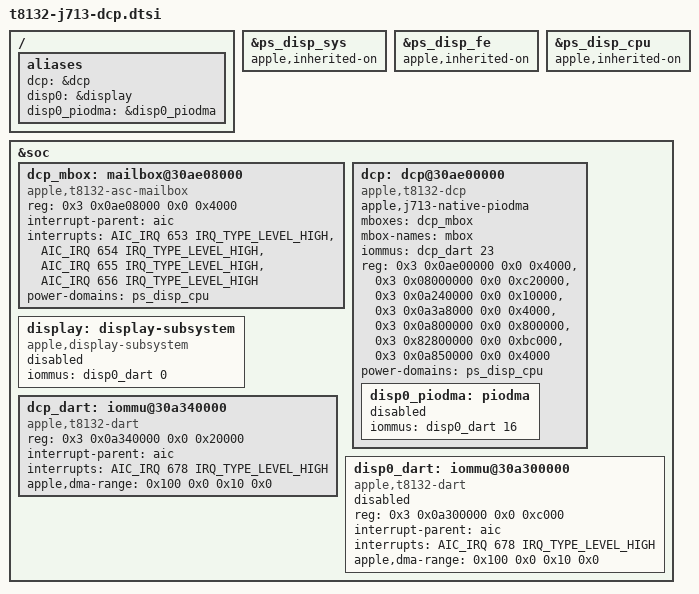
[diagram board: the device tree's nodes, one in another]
// SPDX-License-Identifier: GPL-2.0+ OR MIT
/*
 * J713 internal display resources from its live T8132 ADT.
 * Enable the DCP transport for explicit RTKit bring-up. Scanout and its DART
 * remain disabled. T8132 does not match the imported H17P display driver.
 */

/ {
	aliases {
		dcp = &dcp;
		disp0 = &display;
		disp0_piodma = &disp0_piodma;
	};
};

/* J713 capture: DISP_SYS=0xff, DISP_FE=0x20ff, DISP_CPU=0x1000030f.
 * Keep the inherited power/automatic-gating policy throughout bring-up.
 */
&ps_disp_sys {
	apple,inherited-on;
};

&ps_disp_fe {
	apple,inherited-on;
};

&ps_disp_cpu {
	apple,inherited-on;
};

&soc {
	dcp_mbox: mailbox@30ae08000 {
		compatible = "apple,t8132-asc-mailbox", "apple,asc-mailbox-v4";
		reg = <0x3 0x0ae08000 0x0 0x4000>;
		interrupt-parent = <&aic>;
		/* ADT pairs are not-empty/empty, as on the J713 MTP ASC. */
		interrupts = <AIC_IRQ 653 IRQ_TYPE_LEVEL_HIGH>,
			     <AIC_IRQ 654 IRQ_TYPE_LEVEL_HIGH>,
			     <AIC_IRQ 655 IRQ_TYPE_LEVEL_HIGH>,
			     <AIC_IRQ 656 IRQ_TYPE_LEVEL_HIGH>;
		interrupt-names = "send-empty", "send-not-empty",
				  "recv-empty", "recv-not-empty";
		power-domains = <&ps_disp_cpu>;
		#mbox-cells = <0>;
		status = "okay";
	};

	dcp: dcp@30ae00000 {
		compatible = "apple,t8132-dcp";
		/* m1n1 enables PIODMA only after validating every inherited mapping. */
		apple,j713-native-piodma;
		mboxes = <&dcp_mbox>;
		mbox-names = "mbox";
		iommus = <&dcp_dart 23>;
		reg-names = "coproc", "disp-0", "disp-1", "disp-2",
			    "disp-3", "disp-4", "iop-vbar";
		reg = <0x3 0x0ae00000 0x0 0x4000>,
		      <0x3 0x08000000 0x0 0xc20000>,
		      <0x3 0x0a240000 0x0 0x10000>,
		      <0x3 0x0a3a8000 0x0 0x4000>,
		      <0x3 0x0a800000 0x0 0x800000>,
		      <0x3 0x82800000 0x0 0xbc000>,
		      <0x3 0x0a850000 0x0 0x4000>;
		power-domains = <&ps_disp_cpu>;
		status = "okay";

		/* Address/size tuples for the PIODMA child use 64-bit cells. */
		#address-cells = <2>;
		#size-cells = <2>;

		disp0_piodma: piodma {
			iommus = <&disp0_dart 16>;
			status = "disabled";
		};
	};

	display: display-subsystem {
		compatible = "apple,display-subsystem";
		iommus = <&disp0_dart 0>;
		status = "disabled";
	};

	dcp_dart: iommu@30a340000 {
		compatible = "apple,t8132-dart", "apple,t8110-dart";
		reg = <0x3 0x0a340000 0x0 0x20000>;
		interrupt-parent = <&aic>;
		interrupts = <AIC_IRQ 678 IRQ_TYPE_LEVEL_HIGH>;
		#iommu-cells = <1>;
		/* DCP firmware uses the 1 TiB alias of the locked 36-bit aperture. */
		apple,dma-range = <0x100 0x0 0x10 0x0>;
		status = "okay";
	};

	disp0_dart: iommu@30a300000 {
		compatible = "apple,t8132-dart", "apple,t8110-dart";
		reg = <0x3 0x0a300000 0x0 0xc000>;
		interrupt-parent = <&aic>;
		interrupts = <AIC_IRQ 678 IRQ_TYPE_LEVEL_HIGH>;
		#iommu-cells = <1>;
		apple,dma-range = <0x100 0x0 0x10 0x0>;
		status = "disabled";
	};
};
